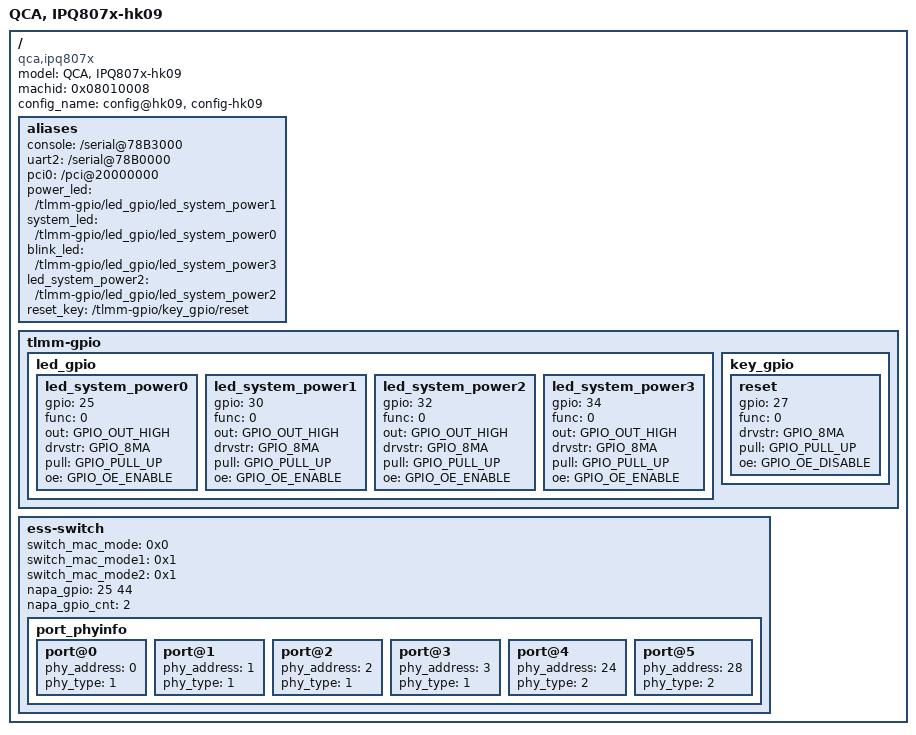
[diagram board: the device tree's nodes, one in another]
/*
 * Copyright (c) 2016 - 2018, The Linux Foundation. All rights reserved.
 *
 * This program is free software; you can redistribute it and/or modify
 * it under the terms of the GNU General Public License version 2 and
 * only version 2 as published by the Free Software Foundation.
 *
 * This program is distributed in the hope that it will be useful,
 * but WITHOUT ANY WARRANTY; without even the implied warranty of
 * MERCHANTABILITY or FITNESS FOR A PARTICULAR PURPOSE.  See the
 * GNU General Public License for more details.
 */

/dts-v1/;
#include "ipq807x-soc.dtsi"
#include <dt-bindings/qcom/gpio-ipq807x.h>
/ {
	model ="QCA, IPQ807x-hk09";
	compatible = "qca,ipq807x", "qca,ipq807x-hk09";
	machid = <0x08010008>;
	config_name = "config@hk09", "config-hk09";

	aliases {
		console = "/serial@78B3000";
		uart2 = "/serial@78B0000";
		pci0 = "/pci@20000000";
		power_led = "/tlmm-gpio/led_gpio/led_system_power1";
		system_led = "/tlmm-gpio/led_gpio/led_system_power0";
		blink_led = "/tlmm-gpio/led_gpio/led_system_power3";
		led_system_power2 = "/tlmm-gpio/led_gpio/led_system_power2";
		reset_key = "/tlmm-gpio/key_gpio/reset";
	};
	tlmm-gpio {
		led_gpio {
			led_system_power0 {
				gpio = <25>;
				func = <0>;
				out = <GPIO_OUT_HIGH>;
				drvstr = <GPIO_8MA>;
				pull = <GPIO_PULL_UP>;
				oe = <GPIO_OE_ENABLE>;
			};
			led_system_power1 {
				gpio = <30>;
				func = <0>;
				out = <GPIO_OUT_HIGH>;
				drvstr = <GPIO_8MA>;
				pull = <GPIO_PULL_UP>;
				oe = <GPIO_OE_ENABLE>;
			};
			led_system_power2 {
				gpio = <32>;
				func = <0>;
				out = <GPIO_OUT_HIGH>;
				drvstr = <GPIO_8MA>;
				pull = <GPIO_PULL_UP>;
				oe = <GPIO_OE_ENABLE>;
			};
			led_system_power3 {
				gpio = <34>;
				func = <0>;
				out = <GPIO_OUT_HIGH>;
				drvstr = <GPIO_8MA>;
				pull = <GPIO_PULL_UP>;
				oe = <GPIO_OE_ENABLE>;
			};
		};
		key_gpio {
			reset {
				gpio = <27>;
				func = <0>;
				drvstr = <GPIO_8MA>;
				pull = <GPIO_PULL_UP>;
				oe = <GPIO_OE_DISABLE>;
			};
		};
	};
	ess-switch {
		switch_mac_mode = <0x0>;
		switch_mac_mode1 = <0x1>;
		switch_mac_mode2 = <0x1>;
		napa_gpio = <25 44>;
		napa_gpio_cnt = <2>;
		port_phyinfo {
			port@0 {
				phy_address = <0>;
				phy_type = <1>;
			};
			port@1 {
				phy_address = <1>;
				phy_type = <1>;
			};
			port@2 {
				phy_address = <2>;
				phy_type = <1>;
			};
			port@3 {
				phy_address = <3>;
				phy_type = <1>;
			};
			port@4 {
				phy_address = <24>;
				phy_type = <2>;
			};
			port@5 {
				phy_address = <28>;
				phy_type = <2>;
			};
		};
	};
};

